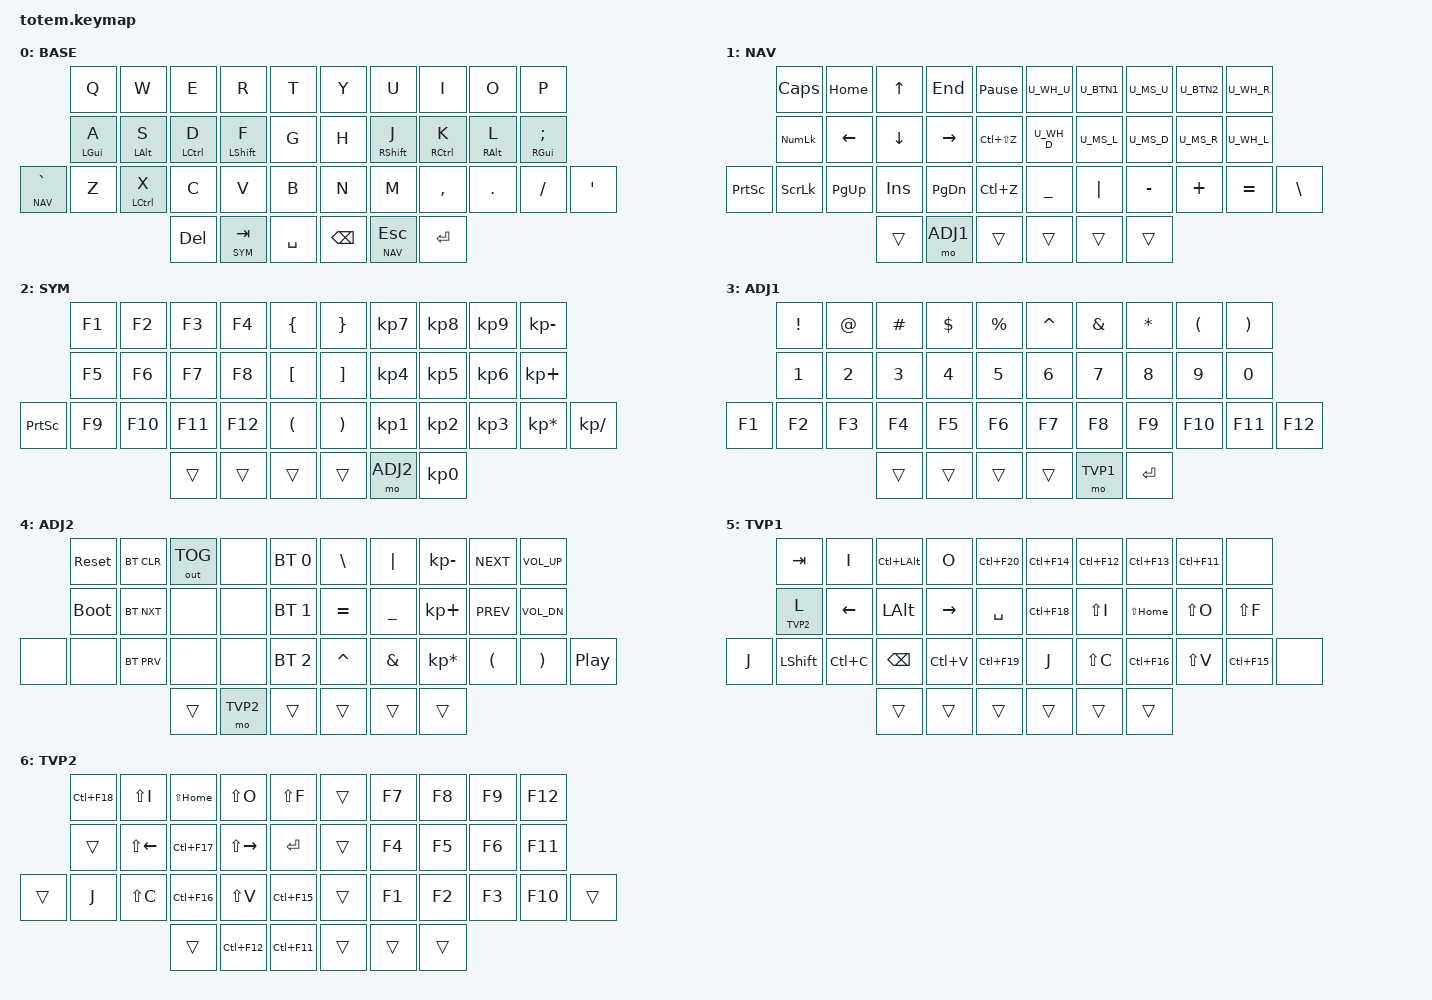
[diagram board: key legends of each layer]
//
//                                                        ▀▀▀▀▀     ▀▀▀▀▀          ▀▀█▀▀
//                                                        ▄▀▀▀▄  ▄  ▄▀▀▀▄  ▄  ▄▀▀▀▄  █  ▄▀▀▀▄
//                                                        █   █  █  █   █  █  █   █  █  █   █
//                                                         ▀▀▀   █   ▀▀▀   █   ▀▀▀   ▀   ▀▀▀
//                                                               █      ▄▄▄█▄▄▄    █   █  
//                                                               ▀      █  █  █     █▄█
//                                                             ▀▀▀▀▀    █  █  █      ▀
//                                                                      ▀  ▀  ▀    G A R R Y
//
// ▄▄▄▄▄▄▄▄▄▄▄▄▄▄▄▄▄▄▄▄▄▄▄▄▄▄▄▄▄▄▄▄▄▄▄▄▄▄▄▄▄▄▄▄▄▄▄▄▄▄▄▄▄▄▄▄▄▄▄▄▄▄▄▄▄▄▄▄▄▄▄▄▄▄▄▄▄▄▄▄▄▄▄▄▄▄▄▄▄▄▄▄▄▄▄▄▄▄▄▄▄▄▄▄▄▄▄▄▄▄▄▄▄▄▄▄▄▄▄▄▄▄▄▄▄▄▄▄▄▄▄▄▄▄▄▄▄▄▄▄▄▄▄▄▄▄▄▄▄

#include <behaviors.dtsi>
#include <dt-bindings/zmk/keys.h>
#include <dt-bindings/zmk/bt.h>
#include <dt-bindings/zmk/outputs.h>
// #include <dt-bindings/zmk/mouse.h>
#include "mouse.dtsi"
// #include "combos.dtsi"  // requires layer aliases
// #include "extra_keys.h"

#define BASE  0
#define NAV   1
#define SYM   2
#define ADJ1  3
#define ADJ2  4
#define TVP1  5
#define TVP2  6

// <--- Mouse --- https://gist.github.com/krissen/dd27082e7ab0575619c7a31f4d2ec7ae --->

// Keymap & Config: https://gist.github.com/krissen/dd27082e7ab0575619c7a31f4d2ec7ae
// West: https://github.com/kagoromo/zmk-config/blob/master/config/west.yml
// Urob: https://github.com/urob/zmk-config#timeless-homerow-mods
// https://www.reddit.com/r/ErgoMechKeyboards/comments/11gejh3/lpt_try_urobs_zmk_timeless_homerow_mods_combos/?rdt=51039

// <--- Mouse END --->

&mt {
  quick-tap-ms = <100>;
  global-quick-tap;
  flavor = "tap-preferred";
  tapping-term-ms = <170>;
};

/ {
     combos {
            compatible = "zmk,combos";
            combo_esc {
                timeout-ms = <50>;
                key-positions = <0 1>;
                bindings = <&kp ESC>;
            };
            combo_tvp {
                timeout-ms = <100>;
                key-positions = <11 12 13>;
                bindings = <&tog TVP1>;
            };
    };

    macros {
        gif: gif {
            label = "giphy";
            compatible = "zmk,behavior-macro";
            #binding-cells = <0>;
            bindings
                = <&macro_press &kp LSHFT>
                , <&macro_tap &kp N2>
                , <&macro_release &kp LSHFT>
                , <&macro_tap &kp G &kp I &kp F>
                ;
        };
    };

        keymap {
                compatible = "zmk,keymap";
// ▄▄▄▄▄▄▄▄▄▄▄▄▄▄▄▄▄▄▄▄▄▄▄▄▄▄▄▄▄▄▄▄▄▄▄▄▄▄▄▄▄▄▄▄▄▄▄▄▄▄▄▄▄▄▄▄▄▄▄▄▄▄▄▄▄▄▄▄▄▄▄▄▄▄▄▄▄▄▄▄▄▄▄▄▄▄▄▄▄▄▄▄▄▄▄▄▄▄▄▄▄▄▄▄▄▄▄▄▄▄▄▄▄▄▄▄▄▄▄▄▄▄▄▄▄▄▄▄▄▄▄▄▄▄▄▄▄▄▄▄▄▄▄▄▄▄▄▄▄

                base_layer {
// ┏━━━━━━━━━━━━━━━━━━━━━━━━━━━━━━━━━━━━━━━┓
label= "BASE"                              ;
// ┗━━━━━━━━━━━━━━━━━━━━━━━━━━━━━━━━━━━━━━━┛
//             ┏━━━━━━━━━━━┳━━━━━━━━━━━┳━━━━━━━━━━━┳━━━━━━━━━━━┳━━━━━━━━━━━┓   ┏━━━━━━━━━━━┳━━━━━━━━━━━┳━━━━━━━━━━━┳━━━━━━━━━━━┳━━━━━━━━━━━┓
//             ┃     Q     ┃     W     ┃     E     ┃     R     ┃     T     ┃   ┃     Y     ┃     U     ┃     I     ┃     O     ┃     P     ┃
//             ┣━━━━━━━━━━━╋━━━━━━━━━━━╋━━━━━━━━━━━╋━━━━━━━━━━━╋━━━━━━━━━━━┫   ┣━━━━━━━━━━━╋━━━━━━━━━━━╋━━━━━━━━━━━╋━━━━━━━━━━━╋━━━━━━━━━━━┫
//             ┃     A     ┃     S     ┃     D     ┃     F     ┃     G     ┃   ┃     H     ┃     J     ┃     K     ┃     L     ┃     ;     ┃
// ┏━━━━━━━━━━━╋━━━━━━━━━━━╋━━━━━━━━━━━╋━━━━━━━━━━━╋━━━━━━━━━━━╋━━━━━━━━━━━┫   ┣━━━━━━━━━━━╋━━━━━━━━━━━╋━━━━━━━━━━━╋━━━━━━━━━━━╋━━━━━━━━━━━╋━━━━━━━━━━━┓
// ┃     `     ┃     Z     ┃     X     ┃     C     ┃     V     ┃     B     ┃   ┃     N     ┃     M     ┃     ,     ┃     .     ┃     /     ┃     '     ┃
// ┗━━━━━━━━━━━┻━━━━━━━━━━━┻━━━━━━━━━━━╋━━━━━━━━━━━╋━━━━━━━━━━━╋━━━━━━━━━━━┫   ┣━━━━━━━━━━━╋━━━━━━━━━━━╋━━━━━━━━━━━╋━━━━━━━━━━━┻━━━━━━━━━━━┻━━━━━━━━━━━┛
//                                     ┃    DEL    ┃    SYM    ┃   SPACE   ┃   ┃   BSPC    ┃    NAV    ┃   ENTER   ┃
//                                     ┗━━━━━━━━━━━┻━━━━━━━━━━━┻━━━━━━━━━━━┛   ┗━━━━━━━━━━━┻━━━━━━━━━━━┻━━━━━━━━━━━┛
 bindings = <
// ╷           ╷           ╷           ╷           ╷           ╷           ╷   ╷           ╷           ╷           ╷           ╷           ╷           ╷

                &kp Q       &kp W       &kp E       &kp R       &kp T           &kp Y       &kp U       &kp I       &kp O       &kp P
                &mt LGUI A  &mt LALT S  &mt LCTRL D &mt LSHFT F &kp G           &kp H       &mt RSHFT J &mt RCTRL K &mt RALT L  &mt RGUI SEMI
  &lt NAV GRAVE &kp Z       &mt LCTRL X &kp C       &kp V       &kp B           &kp N       &kp M       &kp COMMA   &kp DOT     &kp FSLH    &kp APOS
                                        &kp DEL     &lt SYM TAB &kp SPACE       &kp BSPC    &lt NAV ESC &kp RET
                        >;
                };

// ▄▄▄▄▄▄▄▄▄▄▄▄▄▄▄▄▄▄▄▄▄▄▄▄▄▄▄▄▄▄▄▄▄▄▄▄▄▄▄▄▄▄▄▄▄▄▄▄▄▄▄▄▄▄▄▄▄▄▄▄▄▄▄▄▄▄▄▄▄▄▄▄▄▄▄▄▄▄▄▄▄▄▄▄▄▄▄▄▄▄▄▄▄▄▄▄▄▄▄▄▄▄▄▄▄▄▄▄▄▄▄▄▄▄▄▄▄▄▄▄▄▄▄▄▄▄▄▄▄▄▄▄▄▄▄▄▄▄▄▄▄▄▄▄▄▄▄▄▄


                nav_layer {
// ┏━━━━━━━━━━━━━━━━━━━━━━━━━━━━━━━━━━━━━━━┓
label= "NAV"                               ;
// ┗━━━━━━━━━━━━━━━━━━━━━━━━━━━━━━━━━━━━━━━┛
//             ┏━━━━━━━━━━━┳━━━━━━━━━━━┳━━━━━━━━━━━┳━━━━━━━━━━━┳━━━━━━━━━━━┓   ┏━━━━━━━━━━━┳━━━━━━━━━━━┳━━━━━━━━━━━┳━━━━━━━━━━━┳━━━━━━━━━━━┓
//             ┃   CAPS    ┃   HOME    ┃     ↑     ┃    END    ┃   BREAK   ┃   ┃    WH↑    ┃    L_C    ┃    [↑]    ┃    R_C    ┃    WH→    ┃
//             ┣━━━━━━━━━━━╋━━━━━━━━━━━╋━━━━━━━━━━━╋━━━━━━━━━━━╋━━━━━━━━━━━┫   ┣━━━━━━━━━━━╋━━━━━━━━━━━╋━━━━━━━━━━━╋━━━━━━━━━━━╋━━━━━━━━━━━┫
//             ┃   NLCK    ┃     ←     ┃     ↓     ┃     →     ┃   FRWD    ┃   ┃    WH↓    ┃    [←]    ┃    [↓]    ┃    [→]    ┃    ←WH    ┃
// ┏━━━━━━━━━━━╋━━━━━━━━━━━╋━━━━━━━━━━━╋━━━━━━━━━━━╋━━━━━━━━━━━╋━━━━━━━━━━━┫   ┣━━━━━━━━━━━╋━━━━━━━━━━━╋━━━━━━━━━━━╋━━━━━━━━━━━╋━━━━━━━━━━━╋━━━━━━━━━━━┓
// ┃   PSCRN   ┃   SLCK    ┃    PG↓    ┃    INS    ┃    PG↑    ┃   BACK    ┃   ┃     _     ┃     |     ┃     -     ┃     +     ┃     =     ┃     \     ┃
// ┗━━━━━━━━━━━┻━━━━━━━━━━━┻━━━━━━━━━━━╋━━━━━━━━━━━╋━━━━━━━━━━━╋━━━━━━━━━━━┫   ┣━━━━━━━━━━━╋━━━━━━━━━━━╋━━━━━━━━━━━╋━━━━━━━━━━━┻━━━━━━━━━━━┻━━━━━━━━━━━┛
//                                     ┃     ▼     ┃   ADJ1    ┃     ▼     ┃   ┃     ▼     ┃     ▼     ┃     ▼     ┃
//                                     ┗━━━━━━━━━━━┻━━━━━━━━━━━┻━━━━━━━━━━━┛   ┗━━━━━━━━━━━┻━━━━━━━━━━━┻━━━━━━━━━━━┛
 bindings = <
// ╷           ╷           ╷           ╷           ╷           ╷           ╷   ╷           ╷           ╷           ╷           ╷           ╷           ╷

                &kp CAPS     &kp HOME    &kp UP      &kp END     &kp PAUSE_BREAK U_WH_U     U_BTN1      U_MS_U      U_BTN2      U_WH_R
                &kp KP_NLCK  &kp LEFT    &kp DOWN    &kp RIGHT   &kp LC(LS(Z))   U_WH_D     U_MS_L      U_MS_D      U_MS_R      U_WH_L
    &kp PSCRN   &kp SLCK     &kp PG_UP   &kp INS     &kp PG_DN   &kp LC(Z)       &kp UNDER  &kp PIPE    &kp MINUS   &kp PLUS    &kp EQUAL    &kp BSLH      
                                         &trans      &mo ADJ1    &trans          &trans     &trans      &trans
                        >;
                };

// ▄▄▄▄▄▄▄▄▄▄▄▄▄▄▄▄▄▄▄▄▄▄▄▄▄▄▄▄▄▄▄▄▄▄▄▄▄▄▄▄▄▄▄▄▄▄▄▄▄▄▄▄▄▄▄▄▄▄▄▄▄▄▄▄▄▄▄▄▄▄▄▄▄▄▄▄▄▄▄▄▄▄▄▄▄▄▄▄▄▄▄▄▄▄▄▄▄▄▄▄▄▄▄▄▄▄▄▄▄▄▄▄▄▄▄▄▄▄▄▄▄▄▄▄▄▄▄▄▄▄▄▄▄▄▄▄▄▄▄▄▄▄▄▄▄▄▄▄▄


                sym_layer {
// ┏━━━━━━━━━━━━━━━━━━━━━━━━━━━━━━━━━━━━━━━┓
label= "SYM"                              ;
// ┗━━━━━━━━━━━━━━━━━━━━━━━━━━━━━━━━━━━━━━━┛
//             ┏━━━━━━━━━━━┳━━━━━━━━━━━┳━━━━━━━━━━━┳━━━━━━━━━━━┳━━━━━━━━━━━┓   ┏━━━━━━━━━━━┳━━━━━━━━━━━┳━━━━━━━━━━━┳━━━━━━━━━━━┳━━━━━━━━━━━┓
//             ┃    F1     ┃    F2     ┃    F3     ┃    F4     ┃     {     ┃   ┃     }     ┃     7     ┃     8     ┃     9     ┃     -     ┃
//             ┣━━━━━━━━━━━╋━━━━━━━━━━━╋━━━━━━━━━━━╋━━━━━━━━━━━╋━━━━━━━━━━━┫   ┣━━━━━━━━━━━╋━━━━━━━━━━━╋━━━━━━━━━━━╋━━━━━━━━━━━╋━━━━━━━━━━━┫
//             ┃    F5     ┃    F6     ┃    F7     ┃    F8     ┃     [     ┃   ┃     ]     ┃     4     ┃     5     ┃     6     ┃     +     ┃
// ┏━━━━━━━━━━━╋━━━━━━━━━━━╋━━━━━━━━━━━╋━━━━━━━━━━━╋━━━━━━━━━━━╋━━━━━━━━━━━┫   ┣━━━━━━━━━━━╋━━━━━━━━━━━╋━━━━━━━━━━━╋━━━━━━━━━━━╋━━━━━━━━━━━╋━━━━━━━━━━━┓
// ┃   PSCRN   ┃    F9     ┃    F10    ┃    F11    ┃    F12    ┃     (     ┃   ┃     )     ┃     1     ┃     2     ┃     3     ┃     *     ┃     /     ┃
// ┗━━━━━━━━━━━┻━━━━━━━━━━━┻━━━━━━━━━━━╋━━━━━━━━━━━╋━━━━━━━━━━━╋━━━━━━━━━━━┫   ┣━━━━━━━━━━━╋━━━━━━━━━━━╋━━━━━━━━━━━╋━━━━━━━━━━━┻━━━━━━━━━━━┻━━━━━━━━━━━┛
//                                     ┃     ▼     ┃     ▼     ┃     ▼     ┃   ┃     ▼     ┃   ADJ2    ┃     0     ┃
//                                     ┗━━━━━━━━━━━┻━━━━━━━━━━━┻━━━━━━━━━━━┛   ┗━━━━━━━━━━━┻━━━━━━━━━━━┻━━━━━━━━━━━┛
 bindings = <
// ╷           ╷           ╷           ╷           ╷           ╷           ╷   ╷           ╷           ╷           ╷           ╷           ╷           ╷

                &kp F1      &kp F2      &kp F3      &kp F4      &kp LBRC         &kp RBRC    &kp KP_N7   &kp KP_N8   &kp KP_N9   &kp KP_MINUS
                &kp F5      &kp F6      &kp F7      &kp F8      &kp LBKT         &kp RBKT    &kp KP_N4   &kp KP_N5   &kp KP_N6   &kp KP_PLUS
    &kp PSCRN   &kp F9      &kp F10     &kp F11     &kp F12     &kp LPAR         &kp RPAR    &kp KP_N1   &kp KP_N2   &kp KP_N3   &kp KP_MULTIPLY &kp KP_SLASH      
                                        &trans      &trans      &trans           &trans      &mo ADJ2    &kp KP_N0
                        >;
                };

// ▄▄▄▄▄▄▄▄▄▄▄▄▄▄▄▄▄▄▄▄▄▄▄▄▄▄▄▄▄▄▄▄▄▄▄▄▄▄▄▄▄▄▄▄▄▄▄▄▄▄▄▄▄▄▄▄▄▄▄▄▄▄▄▄▄▄▄▄▄▄▄▄▄▄▄▄▄▄▄▄▄▄▄▄▄▄▄▄▄▄▄▄▄▄▄▄▄▄▄▄▄▄▄▄▄▄▄▄▄▄▄▄▄▄▄▄▄▄▄▄▄▄▄▄▄▄▄▄▄▄▄▄▄▄▄▄▄▄▄▄▄▄▄▄▄▄▄▄▄


                adj1_layer {
// ┏━━━━━━━━━━━━━━━━━━━━━━━━━━━━━━━━━━━━━━━┓
label= "ADJ1"                              ;
// ┗━━━━━━━━━━━━━━━━━━━━━━━━━━━━━━━━━━━━━━━┛
//             ┏━━━━━━━━━━━┳━━━━━━━━━━━┳━━━━━━━━━━━┳━━━━━━━━━━━┳━━━━━━━━━━━┓   ┏━━━━━━━━━━━┳━━━━━━━━━━━┳━━━━━━━━━━━┳━━━━━━━━━━━┳━━━━━━━━━━━┓
//             ┃     !     ┃     @     ┃     #     ┃     $     ┃     %     ┃   ┃     ˆ     ┃     &     ┃     *     ┃     (     ┃     )     ┃
//             ┣━━━━━━━━━━━╋━━━━━━━━━━━╋━━━━━━━━━━━╋━━━━━━━━━━━╋━━━━━━━━━━━┫   ┣━━━━━━━━━━━╋━━━━━━━━━━━╋━━━━━━━━━━━╋━━━━━━━━━━━╋━━━━━━━━━━━┫
//             ┃     1     ┃     2     ┃     3     ┃     4     ┃     5     ┃   ┃     6     ┃     7     ┃     8     ┃     9     ┃     0     ┃
// ┏━━━━━━━━━━━╋━━━━━━━━━━━╋━━━━━━━━━━━╋━━━━━━━━━━━╋━━━━━━━━━━━╋━━━━━━━━━━━┫   ┣━━━━━━━━━━━╋━━━━━━━━━━━╋━━━━━━━━━━━╋━━━━━━━━━━━╋━━━━━━━━━━━╋━━━━━━━━━━━┓
// ┃    F1     ┃    F2     ┃    F3     ┃    F4     ┃    F5     ┃    F6     ┃   ┃    F7     ┃    F8     ┃    F9     ┃    F10    ┃    F11    ┃    F12    ┃
// ┗━━━━━━━━━━━┻━━━━━━━━━━━┻━━━━━━━━━━━╋━━━━━━━━━━━╋━━━━━━━━━━━╋━━━━━━━━━━━┫   ┣━━━━━━━━━━━╋━━━━━━━━━━━╋━━━━━━━━━━━╋━━━━━━━━━━━┻━━━━━━━━━━━┻━━━━━━━━━━━┛
//                                     ┃     ▼     ┃     ▼     ┃     ▼     ┃   ┃     ▼     ┃    TVP1   ┃   ENTER   ┃
//                                     ┗━━━━━━━━━━━┻━━━━━━━━━━━┻━━━━━━━━━━━┛   ┗━━━━━━━━━━━┻━━━━━━━━━━━┻━━━━━━━━━━━┛
 bindings = <
// ╷           ╷           ╷           ╷           ╷           ╷           ╷   ╷           ╷           ╷           ╷           ╷           ╷           ╷

                &kp EXCL    &kp AT      &kp HASH    &kp DLLR    &kp PRCNT          &kp CARET   &kp AMPS    &kp STAR    &kp LPAR    &kp RPAR
                &kp N1      &kp N2      &kp N3      &kp N4      &kp N5             &kp N6      &kp N7      &kp N8      &kp N9      &kp N0  
    &kp F1      &kp F2      &kp F3      &kp F4      &kp F5      &kp F6             &kp F7      &kp F8      &kp F9      &kp F10     &kp F11    &kp F12         
                                        &trans      &trans      &trans             &trans      &mo TVP1    &kp RET
                        >;
                };

// ▄▄▄▄▄▄▄▄▄▄▄▄▄▄▄▄▄▄▄▄▄▄▄▄▄▄▄▄▄▄▄▄▄▄▄▄▄▄▄▄▄▄▄▄▄▄▄▄▄▄▄▄▄▄▄▄▄▄▄▄▄▄▄▄▄▄▄▄▄▄▄▄▄▄▄▄▄▄▄▄▄▄▄▄▄▄▄▄▄▄▄▄▄▄▄▄▄▄▄▄▄▄▄▄▄▄▄▄▄▄▄▄▄▄▄▄▄▄▄▄▄▄▄▄▄▄▄▄▄▄▄▄▄▄▄▄▄▄▄▄▄▄▄▄▄▄▄▄▄


                adj2_layer {
// ┏━━━━━━━━━━━━━━━━━━━━━━━━━━━━━━━━━━━━━━━┓
label= "ADJ2"                              ;
// ┗━━━━━━━━━━━━━━━━━━━━━━━━━━━━━━━━━━━━━━━┛
//             ┏━━━━━━━━━━━┳━━━━━━━━━━━┳━━━━━━━━━━━┳━━━━━━━━━━━┳━━━━━━━━━━━┓   ┏━━━━━━━━━━━┳━━━━━━━━━━━┳━━━━━━━━━━━┳━━━━━━━━━━━┳━━━━━━━━━━━┓
//             ┃   RESET   ┃ BT CLEAR  ┃  OUT TOG  ┃           ┃   BT_0    ┃   ┃     \     ┃     |     ┃     -     ┃   NEXT    ┃   VOLU    ┃
//             ┣━━━━━━━━━━━╋━━━━━━━━━━━╋━━━━━━━━━━━╋━━━━━━━━━━━╋━━━━━━━━━━━┫   ┣━━━━━━━━━━━╋━━━━━━━━━━━╋━━━━━━━━━━━╋━━━━━━━━━━━╋━━━━━━━━━━━┫
//             ┃ BOOTLOAD  ┃ BT NEXT   ┃           ┃           ┃   BT_1    ┃   ┃     =     ┃     _     ┃     +     ┃   PREV    ┃   VOLD    ┃
// ┏━━━━━━━━━━━╋━━━━━━━━━━━╋━━━━━━━━━━━╋━━━━━━━━━━━╋━━━━━━━━━━━╋━━━━━━━━━━━┫   ┣━━━━━━━━━━━╋━━━━━━━━━━━╋━━━━━━━━━━━╋━━━━━━━━━━━╋━━━━━━━━━━━╋━━━━━━━━━━━┓
// ┃           ┃           ┃ BT PREV   ┃           ┃           ┃   BT_2    ┃   ┃     ^     ┃     &     ┃     *     ┃     (     ┃     )     ┃   PLAY    ┃
// ┗━━━━━━━━━━━┻━━━━━━━━━━━┻━━━━━━━━━━━╋━━━━━━━━━━━╋━━━━━━━━━━━╋━━━━━━━━━━━┫   ┣━━━━━━━━━━━╋━━━━━━━━━━━╋━━━━━━━━━━━╋━━━━━━━━━━━┻━━━━━━━━━━━┻━━━━━━━━━━━┛
//                                     ┃     ▼     ┃   TVP2    ┃     ▼     ┃   ┃     ▼     ┃     ▼     ┃     ▼     ┃
//                                     ┗━━━━━━━━━━━┻━━━━━━━━━━━┻━━━━━━━━━━━┛   ┗━━━━━━━━━━━┻━━━━━━━━━━━┻━━━━━━━━━━━┛
 bindings = <
// ╷           ╷           ╷           ╷           ╷           ╷           ╷   ╷           ╷           ╷           ╷           ╷           ╷           ╷

                &sys_reset  &bt BT_CLR  &out OUT_TOG &none      &bt BT_SEL 0       &kp BSLH   &kp PIPE   &kp KP_MINUS  &kp C_NEXT  &kp C_VOL_UP
                &bootloader &bt BT_NXT  &none        &none      &bt BT_SEL 1       &kp EQUAL  &kp UNDER  &kp KP_PLUS   &kp C_PREV  &kp C_VOL_DN  
    &none       &none       &bt BT_PRV  &none        &none      &bt BT_SEL 2       &kp CARET  &kp AMPS &kp KP_MULTIPLY &kp LPAR    &kp RPAR   &kp C_PP         
                                        &trans       &mo TVP2   &trans             &trans     &trans     &trans
                        >;
                };

// ▄▄▄▄▄▄▄▄▄▄▄▄▄▄▄▄▄▄▄▄▄▄▄▄▄▄▄▄▄▄▄▄▄▄▄▄▄▄▄▄▄▄▄▄▄▄▄▄▄▄▄▄▄▄▄▄▄▄▄▄▄▄▄▄▄▄▄▄▄▄▄▄▄▄▄▄▄▄▄▄▄▄▄▄▄▄▄▄▄▄▄▄▄▄▄▄▄▄▄▄▄▄▄▄▄▄▄▄▄▄▄▄▄▄▄▄▄▄▄▄▄▄▄▄▄▄▄▄▄▄▄▄▄▄▄▄▄▄▄▄▄▄▄▄▄▄▄▄▄


                tvp1_layer {
// ┏━━━━━━━━━━━━━━━━━━━━━━━━━━━━━━━━━━━━━━━┓
label= "TVP1"                              ;
// ┗━━━━━━━━━━━━━━━━━━━━━━━━━━━━━━━━━━━━━━━┛
//             ┏━━━━━━━━━━━┳━━━━━━━━━━━┳━━━━━━━━━━━┳━━━━━━━━━━━┳━━━━━━━━━━━┓   ┏━━━━━━━━━━━┳━━━━━━━━━━━┳━━━━━━━━━━━┳━━━━━━━━━━━┳━━━━━━━━━━━┓
//             ┃ NEXT FILE ┃ MARK IN   ┃ ROTATE    ┃ MARK OUT  ┃ SHOW SNAP ┃   ┃ UNDO/SAVE ┃ REDO/SAV1 ┃  SEL/MOV  ┃TRANS/WARP ┃           ┃
//             ┣━━━━━━━━━━━╋━━━━━━━━━━━╋━━━━━━━━━━━╋━━━━━━━━━━━╋━━━━━━━━━━━┫   ┣━━━━━━━━━━━╋━━━━━━━━━━━╋━━━━━━━━━━━╋━━━━━━━━━━━╋━━━━━━━━━━━┫
//             ┃ TVP II    ┃ LEFT      ┃ PAN       ┃ RIGHT     ┃ PLAY/FLIP ┃   ┃   SOLO    ┃ TOGGLE IN ┃ RESET ROT ┃ TOGGLE OUT┃ TAKE SNAP ┃
// ┏━━━━━━━━━━━╋━━━━━━━━━━━╋━━━━━━━━━━━╋━━━━━━━━━━━╋━━━━━━━━━━━╋━━━━━━━━━━━┫   ┣━━━━━━━━━━━╋━━━━━━━━━━━╋━━━━━━━━━━━╋━━━━━━━━━━━╋━━━━━━━━━━━╋━━━━━━━━━━━┓
// ┃ FULLSCR   ┃ SHIFT     ┃ COPY      ┃ DELETE    ┃ PASTE     ┃ IMG MARK  ┃   ┃  FULLSCR  ┃ CPY2BRUSH ┃ DEL HEAD  ┃ PSTinPLACE┃ BOOK MARK ┃           ┃
// ┗━━━━━━━━━━━┻━━━━━━━━━━━┻━━━━━━━━━━━╋━━━━━━━━━━━╋━━━━━━━━━━━╋━━━━━━━━━━━┫   ┣━━━━━━━━━━━╋━━━━━━━━━━━╋━━━━━━━━━━━╋━━━━━━━━━━━┻━━━━━━━━━━━┻━━━━━━━━━━━┛
//                                     ┃     ▼     ┃     ▼     ┃     ▼     ┃   ┃     ▼     ┃     ▼     ┃     ▼     ┃
//                                     ┗━━━━━━━━━━━┻━━━━━━━━━━━┻━━━━━━━━━━━┛   ┗━━━━━━━━━━━┻━━━━━━━━━━━┻━━━━━━━━━━━┛
 bindings = <
// ╷           ╷           ╷           ╷           ╷           ╷           ╷   ╷           ╷           ╷           ╷           ╷           ╷           ╷

                &kp TAB     &kp I      &kp LC(LALT) &kp O       &kp LC(F20)     &kp LC(F14) &kp LC(F12) &kp LC(F13)  &kp LC(F11) &none
                &lt TVP2 L  &kp LEFT   &kp LALT     &kp RIGHT   &kp SPACE       &kp LC(F18) &kp LS(I)   &kp LS(HOME) &kp LS(O)   &kp LS(F)
    &kp J       &kp LSHFT   &kp LC(C)  &kp BSPC     &kp LC(V)   &kp LC(F19)     &kp J       &kp LS(C)   &kp LC(F16)  &kp LS(V)   &kp LC(F15) &none        
                                       &trans       &trans      &trans          &trans      &trans      &trans
                        >;
                };

// ▄▄▄▄▄▄▄▄▄▄▄▄▄▄▄▄▄▄▄▄▄▄▄▄▄▄▄▄▄▄▄▄▄▄▄▄▄▄▄▄▄▄▄▄▄▄▄▄▄▄▄▄▄▄▄▄▄▄▄▄▄▄▄▄▄▄▄▄▄▄▄▄▄▄▄▄▄▄▄▄▄▄▄▄▄▄▄▄▄▄▄▄▄▄▄▄▄▄▄▄▄▄▄▄▄▄▄▄▄▄▄▄▄▄▄▄▄▄▄▄▄▄▄▄▄▄▄▄▄▄▄▄▄▄▄▄▄▄▄▄▄▄▄▄▄▄▄▄▄


                tvp2_layer {
// ┏━━━━━━━━━━━━━━━━━━━━━━━━━━━━━━━━━━━━━━━┓
label= "TVP2"                              ;
// ┗━━━━━━━━━━━━━━━━━━━━━━━━━━━━━━━━━━━━━━━┛
//             ┏━━━━━━━━━━━┳━━━━━━━━━━━┳━━━━━━━━━━━┳━━━━━━━━━━━┳━━━━━━━━━━━┓   ┏━━━━━━━━━━━┳━━━━━━━━━━━┳━━━━━━━━━━━┳━━━━━━━━━━━┳━━━━━━━━━━━┓
//             ┃   SOLO    ┃ TOGGLE IN ┃ RESET ROT ┃ TOGGLE OUT┃ TAKE SNAP ┃   ┃           ┃           ┃           ┃           ┃           ┃
//             ┣━━━━━━━━━━━╋━━━━━━━━━━━╋━━━━━━━━━━━╋━━━━━━━━━━━╋━━━━━━━━━━━┫   ┣━━━━━━━━━━━╋━━━━━━━━━━━╋━━━━━━━━━━━╋━━━━━━━━━━━╋━━━━━━━━━━━┫
//             ┃           ┃ LAST KEY  ┃ NEW KEY   ┃ NEXT KEY  ┃   ENTER   ┃   ┃           ┃           ┃           ┃           ┃           ┃
// ┏━━━━━━━━━━━╋━━━━━━━━━━━╋━━━━━━━━━━━╋━━━━━━━━━━━╋━━━━━━━━━━━╋━━━━━━━━━━━┫   ┣━━━━━━━━━━━╋━━━━━━━━━━━╋━━━━━━━━━━━╋━━━━━━━━━━━╋━━━━━━━━━━━╋━━━━━━━━━━━┓
// ┃           ┃  FULLSCR  ┃ CPY2BRUSH ┃ DEL HEAD  ┃ PSTinPLACE┃ BOOK MARK ┃   ┃           ┃           ┃           ┃           ┃           ┃           ┃
// ┗━━━━━━━━━━━┻━━━━━━━━━━━┻━━━━━━━━━━━╋━━━━━━━━━━━╋━━━━━━━━━━━╋━━━━━━━━━━━┫   ┣━━━━━━━━━━━╋━━━━━━━━━━━╋━━━━━━━━━━━╋━━━━━━━━━━━┻━━━━━━━━━━━┻━━━━━━━━━━━┛
//                                     ┃           ┃ REDO/SAV1 ┃TRANS/WARP ┃   ┃           ┃           ┃           ┃
//                                     ┗━━━━━━━━━━━┻━━━━━━━━━━━┻━━━━━━━━━━━┛   ┗━━━━━━━━━━━┻━━━━━━━━━━━┻━━━━━━━━━━━┛
 bindings = <
// ╷           ╷           ╷           ╷           ╷           ╷           ╷   ╷           ╷           ╷           ╷           ╷           ╷           ╷

                &kp LC(F18) &kp LS(I)  &kp LS(HOME) &kp LS(O)   &kp LS(F)       &trans      &kp F7      &kp F8      &kp F9      &kp F12
                &trans    &kp LS(LEFT) &kp LC(F17)  &kp LS(RIGHT) &kp RET       &trans      &kp F4      &kp F5      &kp F6      &kp F11  
    &trans      &kp J       &kp LS(C)  &kp LC(F16)  &kp LS(V)   &kp LC(F15)     &trans      &kp F1      &kp F2      &kp F3      &kp F10     &trans         
                                        &trans      &kp LC(F12) &kp LC(F11)     &trans      &trans      &trans
                        >;
                };
        };
};
